AUTOSAR XML (schema 4-3-0)
package /CAN3/ISignalGroup
  11 x i signal group:
    CAN3_SG_BMS1: i-signal=CAN3_HVBattVolt, system-signal-group=CAN3_SG_BMS1
    CAN3_SG_BMS6: i-signal=CAN3_HVBContactorSta, system-signal-group=CAN3_SG_BMS6
    CAN3_SG_FD3_C100_0: i-signal=[CAN3_BatteryMode, CAN3_Rr_Coolantflow, CAN3_Rr_Coolanttemp], system-signal-group=CAN3_SG_FD3_C100_0
    CAN3_SG_FD3_VCU1: i-signal=[CAN3_ActiveDischReq, CAN3_CS_VCU1, CAN3_PwrSta, CAN3_RC_VCU1, CAN3_ShiftGearPosn], system-signal-group=CAN3_SG_FD3_VCU1
    CAN3_SG_FD3_VCU2: i-signal=[CAN3_CS_VCU2_CAN1, CAN3_RC_VCU2_CAN1, CAN3_Rr_ActvDmpDisabReq, CAN3_Rr_IdcMax, CAN3_Rr_IdcMin, CAN3_Rr_MCUEnaReq, CAN3_Rr_TMTqReq, CAN3_Rr_TorqMax, CAN3_Rr_TorqMin, CAN3_Rr_UdcMax, CAN3_Rr_UdcMin], system-signal-group=CAN3_SG_FD3_VCU2
    CAN3_SG_FD3_VCU5: i-signal=[CAN3_FDC_VCU_RrSpdMax_Req, CAN3_FDC_VCU_RrSpdMin_Req, CAN3_FDC_VCU_RrTMCtrlMode_Req, CAN3_FDC_VCU_RrTMSpd_Req, CAN3_FDC_VCU_RrTMTq_Req, CAN3_FDC_VCU_RrTqMax_Req, CAN3_FDC_VCU_RrTqMin_Req], system-signal-group=CAN3_SG_FD3_VCU5
    CAN3_SG_GW3_CE100_0: i-signal=[CAN3_IVI_Time_Day, CAN3_IVI_Time_Hour, CAN3_IVI_Time_Minute, CAN3_IVI_Time_Month, CAN3_IVI_Time_Second, CAN3_VehSpeed], system-signal-group=CAN3_SG_GW3_CE100_0
    CAN3_SG_MCU_B_R1: i-signal=[CAN3_MCUWarn_R, CAN3_MCU_B_R_IGBTDdeTemp_Sta, CAN3_MCU_B_R_RealPwrKw_Sta, CAN3_Rr_ActvDmpDisabSta, CAN3_Rr_EDUDrtSta, CAN3_Rr_EDUOpratingSta, CAN3_Rr_EDURealTMTq, CAN3_Rr_EDURotateDirction, CAN3_Rr_EDUTqReqFbk, CAN3_Rr_MCU1Chksum, CAN3_Rr_MCU1RolCnt, CAN3_Rr_MCUBAT, CAN3_Rr_MCUDCBusCurr, CAN3_Rr_MCUDCBusVolt, CAN3_Rr_MCUDischrgSta, CAN3_Rr_MCUEnaSta, CAN3_Rr_MCUErr, CAN3_Rr_MCUIGN_sta, CAN3_Rr_MCUReady, CAN3_Rr_MCUReady4Pre, CAN3_Rr_MCUSysSta, CAN3_Rr_MCUTemp, CAN3_Rr_MotorAvailTq, CAN3_Rr_RegenAvailTq, CAN3_Rr_Reserved_bits, CAN3_Rr_TMSpd, CAN3_Rr_TMTemp, CAN3_Rr_TMid, CAN3_Rr_TMiq], system-signal-group=CAN3_SG_MCU_B_R1
    CAN3_SG_MCU_B_R2: i-signal=[CAN3_MCU_B_R_FailLv_Sta, CAN3_MCU_B_R_KL302TqCnt_Sta, CAN3_MCU_B_R_LLCTempWarn_Sta, CAN3_Rr_CoolanttempReq, CAN3_Rr_Failcode1, CAN3_Rr_Failcode2, CAN3_Rr_Failcodehistory1, CAN3_Rr_Failcodehistory2, CAN3_Rr_LLCTemp, CAN3_Rr_LLCflowReq, CAN3_Rr_MCU2Chksum, CAN3_Rr_MCU2RolCnt, CAN3_Rr_MCU3_HW_Ver, CAN3_Rr_MCU3_SW_Ver, CAN3_Rr_MCUTempWarn, CAN3_Rr_TMTempWarn], system-signal-group=CAN3_SG_MCU_B_R2
    CAN3_SG_MCU_B_R_Debug1: i-signal=[CAN3_MCU_R_ID_REF, CAN3_MCU_R_IQ_REF, CAN3_MCU_R_Reserve0, CAN3_MCU_R_Reserve1, CAN3_MCU_R_Reserve2, CAN3_R_FD_FACTCODE_N, CAN3_R_FD_FACTCODE_P, CAN3_R_ID_TQ_LIM_N, CAN3_R_ID_TQ_LIM_P, CAN3_R_K_TQ_LIM_N, CAN3_R_K_TQ_LIM_P, CAN3_R_OffsetAngle, CAN3_R_TQ_LIM_N, CAN3_R_TQ_LIM_P], system-signal-group=CAN3_SG_MCU_B_R_Debug1
    CAN3_SG_MCU_FVT_R1: i-signal=[CAN3_MCU_FVT_R_BoostOP_Sta, CAN3_MCU_FVT_R_EDUTqReq_Fbk, CAN3_MCU_FVT_R_Failcode3_Sta, CAN3_MCU_FVT_R_HeatingOP_Sta, CAN3_MCU_FVT_R_MCUBAT_Sta, CAN3_MCU_FVT_R_MCUErr_Sta, CAN3_MCU_FVT_R_MCUSys_Sta, CAN3_MCU_FVT_R_OilTemp_Sta, CAN3_MCU_FVT_R_TMSpd_Sta], system-signal-group=CAN3_SG_MCU_FVT_R1
package /CAN3/Cluster
  can cluster CAN3: baudrate=500, can-fd-baudrate=2000
    can physical channel CAN3: comm-connectors=ConnCAN3
      frame CAN3_BMS1: id 0x171, frame-length=16, can-addressing-mode=STANDARD, can-fd-frame-support=true, can-frame-rx-behavior=CAN-FD, can-frame-tx-behavior=CAN-FD
        pdu CAN3_BMS1: length=16, minimum-delay=0.0, transmission-mode-true-timing=cyclic-timing=time-period=0.01, unused-bit-pattern=0
          mapping CAN3_SG_BMS1: i-signal-group=CAN3_SG_BMS1, start-position=0, transfer-property=PENDING
          signal CAN3_HVBattVolt: start 28, 13 bit, big-endian, i-signal-type=PRIMITIVE, init-value=constant-reference=Init_CAN3_HVBattVolt, base-type=uint16, implementation-data-type=uint16, transfer-property=PENDING
      frame CAN3_BMS6: id 0x17A, frame-length=12, can-addressing-mode=STANDARD, can-fd-frame-support=true, can-frame-rx-behavior=CAN-FD, can-frame-tx-behavior=CAN-FD
        pdu CAN3_BMS6: length=12, minimum-delay=0.0, transmission-mode-true-timing={cyclic-timing=time-period=0.1, event-controlled-timing={number-of-repetitions=0, repetition-period=0}}, unused-bit-pattern=0
          mapping CAN3_SG_BMS6: i-signal-group=CAN3_SG_BMS6, start-position=0, transfer-property=TRIGGERED-ON-CHANGE
          signal CAN3_HVBContactorSta: start 66, 1 bit, big-endian, i-signal-type=PRIMITIVE, init-value=constant-reference=Init_CAN3_HVBContactorSta, base-type=uint8, implementation-data-type=uint8, transfer-property=TRIGGERED-ON-CHANGE
      frame CAN3_DiagFuncReqFT: id 0x7D0, frame-length=8, can-addressing-mode=STANDARD, can-fd-frame-support=true, can-frame-rx-behavior=CAN-FD, can-frame-tx-behavior=CAN-FD
        n pdu CAN3_DiagFuncReqFT: length=8
      frame CAN3_DiagFuncReqOBD: id 0x7DF, frame-length=8, can-addressing-mode=STANDARD, can-fd-frame-support=true, can-frame-rx-behavior=CAN-FD, can-frame-tx-behavior=CAN-FD
        n pdu CAN3_DiagFuncReqOBD: length=8
      frame CAN3_DiagPhysReqToEOP_FVT_R: id 0x6C3, frame-length=8, can-addressing-mode=STANDARD, can-fd-frame-support=true, can-frame-rx-behavior=CAN-FD, can-frame-tx-behavior=CAN-FD
        n pdu CAN3_DiagPhysReqToEOP_FVT_R: length=8
      frame CAN3_DiagPhysReqToMCU_B_R: id 0x689, frame-length=64, can-addressing-mode=STANDARD, can-fd-frame-support=true, can-frame-rx-behavior=CAN-FD, can-frame-tx-behavior=CAN-FD
        n pdu CAN3_DiagPhysReqToMCU_B_R: length=8
      frame CAN3_DiagRespFromEOP_FVT_R: id 0x643, frame-length=8, can-addressing-mode=STANDARD, can-fd-frame-support=true, can-frame-rx-behavior=CAN-FD, can-frame-tx-behavior=CAN-FD
        n pdu CAN3_DiagRespFromEOP_FVT_R: length=8
      frame CAN3_DiagRespFromMCU_B_R: id 0x609, frame-length=64, can-addressing-mode=STANDARD, can-fd-frame-support=true, can-frame-rx-behavior=CAN-FD, can-frame-tx-behavior=CAN-FD
        n pdu CAN3_DiagRespFromMCU_B_R: length=8
      frame CAN3_FD3_C100_0: id 0x182, frame-length=20, can-addressing-mode=STANDARD, can-fd-frame-support=true, can-frame-rx-behavior=CAN-FD, can-frame-tx-behavior=CAN-FD
        pdu CAN3_FD3_C100_0: length=20, minimum-delay=0.0, transmission-mode-true-timing=cyclic-timing=time-period=0.1, unused-bit-pattern=0
          mapping CAN3_SG_FD3_C100_0: i-signal-group=CAN3_SG_FD3_C100_0, start-position=0, transfer-property=PENDING
          signal CAN3_BatteryMode: start 118, 3 bit, big-endian, i-signal-type=PRIMITIVE, init-value=constant-reference=Init_CAN3_BatteryMode, base-type=uint8, implementation-data-type=uint8, transfer-property=PENDING
          signal CAN3_Rr_Coolantflow: start 150, 6 bit, big-endian, i-signal-type=PRIMITIVE, init-value=constant-reference=Init_CAN3_Rr_Coolantflow, base-type=uint8, implementation-data-type=uint8, transfer-property=PENDING
          signal CAN3_Rr_Coolanttemp: start 144, 9 bit, big-endian, i-signal-type=PRIMITIVE, init-value=constant-reference=Init_CAN3_Rr_Coolanttemp, base-type=uint16, implementation-data-type=uint16, transfer-property=PENDING
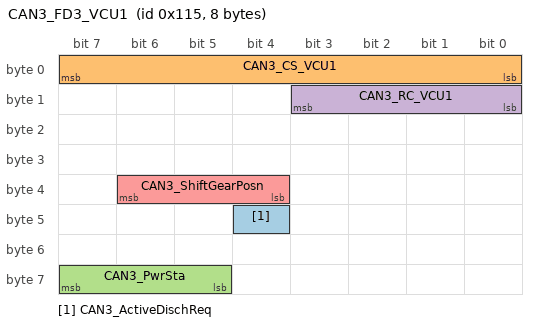
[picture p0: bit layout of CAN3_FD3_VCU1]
      frame CAN3_FD3_VCU1: id 0x115, frame-length=8, can-addressing-mode=STANDARD, can-fd-frame-support=true, can-frame-rx-behavior=CAN-FD, can-frame-tx-behavior=CAN-FD
        pdu CAN3_FD3_VCU1: length=8, minimum-delay=0.0, transmission-mode-true-timing={cyclic-timing=time-period=0.1, event-controlled-timing={number-of-repetitions=0, repetition-period=0}}, unused-bit-pattern=0
          mapping CAN3_SG_FD3_VCU1: i-signal-group=CAN3_SG_FD3_VCU1, start-position=0, transfer-property=TRIGGERED-ON-CHANGE
          signal CAN3_ActiveDischReq: start 44, 1 bit, big-endian, i-signal-type=PRIMITIVE, init-value=constant-reference=Init_CAN3_ActiveDischReq, base-type=uint8, implementation-data-type=uint8, transfer-property=TRIGGERED-ON-CHANGE
          signal CAN3_CS_VCU1: start 7, 8 bit, big-endian, i-signal-type=PRIMITIVE, init-value=constant-reference=Init_CAN3_CS_VCU1, base-type=uint8, implementation-data-type=uint8, transfer-property=PENDING
          signal CAN3_PwrSta: start 63, 3 bit, big-endian, i-signal-type=PRIMITIVE, init-value=constant-reference=Init_CAN3_PwrSta, base-type=uint8, implementation-data-type=uint8, transfer-property=TRIGGERED-ON-CHANGE
          signal CAN3_RC_VCU1: start 11, 4 bit, big-endian, i-signal-type=PRIMITIVE, init-value=constant-reference=Init_CAN3_RC_VCU1, base-type=uint8, implementation-data-type=uint8, transfer-property=PENDING
          signal CAN3_ShiftGearPosn: start 38, 3 bit, big-endian, i-signal-type=PRIMITIVE, init-value=constant-reference=Init_CAN3_ShiftGearPosn, base-type=uint8, implementation-data-type=uint8, transfer-property=TRIGGERED-ON-CHANGE
      frame CAN3_FD3_VCU2: id 0x153, frame-length=32, can-addressing-mode=STANDARD, can-fd-frame-support=true, can-frame-rx-behavior=CAN-FD, can-frame-tx-behavior=CAN-FD
        pdu CAN3_FD3_VCU2: length=32, minimum-delay=0.0, transmission-mode-true-timing=cyclic-timing=time-period=0.01, unused-bit-pattern=0
          mapping CAN3_SG_FD3_VCU2: i-signal-group=CAN3_SG_FD3_VCU2, start-position=0, transfer-property=PENDING
          signal CAN3_CS_VCU2_CAN1: start 7, 8 bit, big-endian, i-signal-type=PRIMITIVE, init-value=constant-reference=Init_CAN3_CS_VCU2_CAN1, base-type=uint8, implementation-data-type=uint8, transfer-property=PENDING
          signal CAN3_RC_VCU2_CAN1: start 11, 4 bit, big-endian, i-signal-type=PRIMITIVE, init-value=constant-reference=Init_CAN3_RC_VCU2_CAN1, base-type=uint8, implementation-data-type=uint8, transfer-property=PENDING
          signal CAN3_Rr_ActvDmpDisabReq: start 196, 1 bit, big-endian, i-signal-type=PRIMITIVE, init-value=constant-reference=Init_CAN3_Rr_ActvDmpDisabReq, base-type=uint8, implementation-data-type=uint8, transfer-property=PENDING
          signal CAN3_Rr_IdcMax: start 23, 12 bit, big-endian, i-signal-type=PRIMITIVE, init-value=constant-reference=Init_CAN3_Rr_IdcMax, base-type=uint16, implementation-data-type=uint16, transfer-property=PENDING
          signal CAN3_Rr_IdcMin: start 27, 12 bit, big-endian, i-signal-type=PRIMITIVE, init-value=constant-reference=Init_CAN3_Rr_IdcMin, base-type=uint16, implementation-data-type=uint16, transfer-property=PENDING
          signal CAN3_Rr_MCUEnaReq: start 197, 1 bit, big-endian, i-signal-type=PRIMITIVE, init-value=constant-reference=Init_CAN3_Rr_MCUEnaReq, base-type=uint8, implementation-data-type=uint8, transfer-property=PENDING
          signal CAN3_Rr_TMTqReq: start 119, 16 bit, big-endian, i-signal-type=PRIMITIVE, init-value=constant-reference=Init_CAN3_Rr_TMTqReq, base-type=uint16, implementation-data-type=uint16, transfer-property=PENDING
          signal CAN3_Rr_TorqMax: start 47, 12 bit, big-endian, i-signal-type=PRIMITIVE, init-value=constant-reference=Init_CAN3_Rr_TorqMax, base-type=uint16, implementation-data-type=uint16, transfer-property=PENDING
          signal CAN3_Rr_TorqMin: start 51, 12 bit, big-endian, i-signal-type=PRIMITIVE, init-value=constant-reference=Init_CAN3_Rr_TorqMin, base-type=uint16, implementation-data-type=uint16, transfer-property=PENDING
          signal CAN3_Rr_UdcMax: start 71, 12 bit, big-endian, i-signal-type=PRIMITIVE, init-value=constant-reference=Init_CAN3_Rr_UdcMax, base-type=uint16, implementation-data-type=uint16, transfer-property=PENDING
          signal CAN3_Rr_UdcMin: start 75, 12 bit, big-endian, i-signal-type=PRIMITIVE, init-value=constant-reference=Init_CAN3_Rr_UdcMin, base-type=uint16, implementation-data-type=uint16, transfer-property=PENDING
      frame CAN3_FD3_VCU5: id 0x155, frame-length=32, can-addressing-mode=STANDARD, can-fd-frame-support=true, can-frame-rx-behavior=CAN-FD, can-frame-tx-behavior=CAN-FD
        pdu CAN3_FD3_VCU5: length=32, minimum-delay=0.0, transmission-mode-true-timing=cyclic-timing=time-period=0.01, unused-bit-pattern=0
          mapping CAN3_SG_FD3_VCU5: i-signal-group=CAN3_SG_FD3_VCU5, start-position=0, transfer-property=PENDING
          signal CAN3_FDC_VCU_RrSpdMax_Req: start 103, 16 bit, big-endian, i-signal-type=PRIMITIVE, init-value=constant-reference=Init_CAN3_FDC_VCU_RrSpdMax_Req, base-type=uint16, implementation-data-type=uint16, transfer-property=PENDING
          signal CAN3_FDC_VCU_RrSpdMin_Req: start 135, 16 bit, big-endian, i-signal-type=PRIMITIVE, init-value=constant-reference=Init_CAN3_FDC_VCU_RrSpdMin_Req, base-type=uint16, implementation-data-type=uint16, transfer-property=PENDING
          signal CAN3_FDC_VCU_RrTMCtrlMode_Req: start 47, 3 bit, big-endian, i-signal-type=PRIMITIVE, init-value=constant-reference=Init_CAN3_FDC_VCU_RrTMCtrlMode_Req, base-type=uint8, implementation-data-type=uint8, transfer-property=PENDING
          signal CAN3_FDC_VCU_RrTMSpd_Req: start 167, 16 bit, big-endian, i-signal-type=PRIMITIVE, init-value=constant-reference=Init_CAN3_FDC_VCU_RrTMSpd_Req, base-type=uint16, implementation-data-type=uint16, transfer-property=PENDING
          signal CAN3_FDC_VCU_RrTMTq_Req: start 199, 16 bit, big-endian, i-signal-type=PRIMITIVE, init-value=constant-reference=Init_CAN3_FDC_VCU_RrTMTq_Req, base-type=uint16, implementation-data-type=uint16, transfer-property=PENDING
          signal CAN3_FDC_VCU_RrTqMax_Req: start 219, 12 bit, big-endian, i-signal-type=PRIMITIVE, init-value=constant-reference=Init_CAN3_FDC_VCU_RrTqMax_Req, base-type=uint16, implementation-data-type=uint16, transfer-property=PENDING
          signal CAN3_FDC_VCU_RrTqMin_Req: start 243, 12 bit, big-endian, i-signal-type=PRIMITIVE, init-value=constant-reference=Init_CAN3_FDC_VCU_RrTqMin_Req, base-type=uint16, implementation-data-type=uint16, transfer-property=PENDING
      frame CAN3_GW3_CE100_0: id 0x1C3, frame-length=32, can-addressing-mode=STANDARD, can-fd-frame-support=true, can-frame-rx-behavior=CAN-FD, can-frame-tx-behavior=CAN-FD
        pdu CAN3_GW3_CE100_0: length=32, minimum-delay=0.0, transmission-mode-true-timing={cyclic-timing=time-period=0.1, event-controlled-timing={number-of-repetitions=0, repetition-period=0}}, unused-bit-pattern=0
          mapping CAN3_SG_GW3_CE100_0: i-signal-group=CAN3_SG_GW3_CE100_0, start-position=0, transfer-property=TRIGGERED-ON-CHANGE
          signal CAN3_IVI_Time_Day: start 228, 5 bit, big-endian, i-signal-type=PRIMITIVE, init-value=constant-reference=Init_CAN3_IVI_Time_Day, base-type=uint8, implementation-data-type=uint8, transfer-property=PENDING
          signal CAN3_IVI_Time_Hour: start 236, 5 bit, big-endian, i-signal-type=PRIMITIVE, init-value=constant-reference=Init_CAN3_IVI_Time_Hour, base-type=uint8, implementation-data-type=uint8, transfer-property=PENDING
          signal CAN3_IVI_Time_Minute: start 245, 6 bit, big-endian, i-signal-type=PRIMITIVE, init-value=constant-reference=Init_CAN3_IVI_Time_Minute, base-type=uint8, implementation-data-type=uint8, transfer-property=PENDING
          signal CAN3_IVI_Time_Month: start 219, 4 bit, big-endian, i-signal-type=PRIMITIVE, init-value=constant-reference=Init_CAN3_IVI_Time_Month, base-type=uint8, implementation-data-type=uint8, transfer-property=PENDING
          signal CAN3_IVI_Time_Second: start 253, 6 bit, big-endian, i-signal-type=PRIMITIVE, init-value=constant-reference=Init_CAN3_IVI_Time_Second, base-type=uint8, implementation-data-type=uint8, transfer-property=PENDING
          signal CAN3_VehSpeed: start 19, 12 bit, big-endian, i-signal-type=PRIMITIVE, init-value=constant-reference=Init_CAN3_VehSpeed, base-type=uint16, implementation-data-type=uint16, transfer-property=PENDING
      frame CAN3_MCU_B_R1: id 0x190, frame-length=32, can-addressing-mode=STANDARD, can-fd-frame-support=true, can-frame-rx-behavior=CAN-FD, can-frame-tx-behavior=CAN-FD
        pdu CAN3_MCU_B_R1: length=32, minimum-delay=0.0, transmission-mode-true-timing=cyclic-timing=time-period=0.01, unused-bit-pattern=0
          mapping CAN3_SG_MCU_B_R1: i-signal-group=CAN3_SG_MCU_B_R1, start-position=0, transfer-property=PENDING
          signal CAN3_MCUWarn_R: start 62, 3 bit, big-endian, i-signal-type=PRIMITIVE, init-value=constant-reference=Init_CAN3_MCUWarn_R, base-type=uint8, implementation-data-type=uint8, transfer-property=PENDING
          signal CAN3_MCU_B_R_IGBTDdeTemp_Sta: start 24, 9 bit, big-endian, i-signal-type=PRIMITIVE, init-value=constant-reference=Init_CAN3_MCU_B_R_IGBTDdeTemp_Sta, base-type=uint16, implementation-data-type=uint16, transfer-property=PENDING
          signal CAN3_MCU_B_R_RealPwrKw_Sta: start 47, 16 bit, big-endian, i-signal-type=PRIMITIVE, init-value=constant-reference=Init_CAN3_MCU_B_R_RealPwrKw_Sta, base-type=uint16, implementation-data-type=uint16, transfer-property=PENDING
          signal CAN3_Rr_ActvDmpDisabSta: start 201, 1 bit, big-endian, i-signal-type=PRIMITIVE, init-value=constant-reference=Init_CAN3_Rr_ActvDmpDisabSta, base-type=uint8, implementation-data-type=uint8, transfer-property=PENDING
          signal CAN3_Rr_EDUDrtSta: start 202, 1 bit, big-endian, i-signal-type=PRIMITIVE, init-value=constant-reference=Init_CAN3_Rr_EDUDrtSta, base-type=uint8, implementation-data-type=uint8, transfer-property=PENDING
          signal CAN3_Rr_EDUOpratingSta: start 245, 1 bit, big-endian, i-signal-type=PRIMITIVE, init-value=constant-reference=Init_CAN3_Rr_EDUOpratingSta, base-type=uint8, implementation-data-type=uint8, transfer-property=PENDING
          signal CAN3_Rr_EDURealTMTq: start 231, 16 bit, big-endian, i-signal-type=PRIMITIVE, init-value=constant-reference=Init_CAN3_Rr_EDURealTMTq, base-type=uint16, implementation-data-type=uint16, transfer-property=PENDING
          signal CAN3_Rr_EDURotateDirction: start 247, 2 bit, big-endian, i-signal-type=PRIMITIVE, init-value=constant-reference=Init_CAN3_Rr_EDURotateDirction, base-type=uint8, implementation-data-type=uint8, transfer-property=PENDING
          signal CAN3_Rr_EDUTqReqFbk: start 243, 12 bit, big-endian, i-signal-type=PRIMITIVE, init-value=constant-reference=Init_CAN3_Rr_EDUTqReqFbk, base-type=uint16, implementation-data-type=uint16, transfer-property=PENDING
          signal CAN3_Rr_MCU1Chksum: start 7, 8 bit, big-endian, i-signal-type=PRIMITIVE, init-value=constant-reference=Init_CAN3_Rr_MCU1Chksum, base-type=uint8, implementation-data-type=uint8, transfer-property=PENDING
          signal CAN3_Rr_MCU1RolCnt: start 11, 4 bit, big-endian, i-signal-type=PRIMITIVE, init-value=constant-reference=Init_CAN3_Rr_MCU1RolCnt, base-type=uint8, implementation-data-type=uint8, transfer-property=PENDING
          signal CAN3_Rr_MCUBAT: start 71, 8 bit, big-endian, i-signal-type=PRIMITIVE, init-value=constant-reference=Init_CAN3_Rr_MCUBAT, base-type=uint8, implementation-data-type=uint8, transfer-property=PENDING
          signal CAN3_Rr_MCUDCBusCurr: start 174, 15 bit, big-endian, i-signal-type=PRIMITIVE, init-value=constant-reference=Init_CAN3_Rr_MCUDCBusCurr, base-type=uint16, implementation-data-type=uint16, transfer-property=PENDING
          signal CAN3_Rr_MCUDCBusVolt: start 191, 16 bit, big-endian, i-signal-type=PRIMITIVE, init-value=constant-reference=Init_CAN3_Rr_MCUDCBusVolt, base-type=uint16, implementation-data-type=uint16, transfer-property=PENDING
          signal CAN3_Rr_MCUDischrgSta: start 203, 1 bit, big-endian, i-signal-type=PRIMITIVE, init-value=constant-reference=Init_CAN3_Rr_MCUDischrgSta, base-type=uint8, implementation-data-type=uint8, transfer-property=PENDING
          signal CAN3_Rr_MCUEnaSta: start 244, 1 bit, big-endian, i-signal-type=PRIMITIVE, init-value=constant-reference=Init_CAN3_Rr_MCUEnaSta, base-type=uint8, implementation-data-type=uint8, transfer-property=PENDING
          signal CAN3_Rr_MCUErr: start 143, 8 bit, big-endian, i-signal-type=PRIMITIVE, init-value=constant-reference=Init_CAN3_Rr_MCUErr, base-type=uint8, implementation-data-type=uint8, transfer-property=PENDING
          signal CAN3_Rr_MCUIGN_sta: start 72, 1 bit, big-endian, i-signal-type=PRIMITIVE, init-value=constant-reference=Init_CAN3_Rr_MCUIGN_sta, base-type=uint8, implementation-data-type=uint8, transfer-property=PENDING
          signal CAN3_Rr_MCUReady: start 63, 1 bit, big-endian, i-signal-type=PRIMITIVE, init-value=constant-reference=Init_CAN3_Rr_MCUReady, base-type=uint8, implementation-data-type=uint8, transfer-property=PENDING
          signal CAN3_Rr_MCUReady4Pre: start 200, 1 bit, big-endian, i-signal-type=PRIMITIVE, init-value=constant-reference=Init_CAN3_Rr_MCUReady4Pre, base-type=uint8, implementation-data-type=uint8, transfer-property=PENDING
          signal CAN3_Rr_MCUSysSta: start 59, 4 bit, big-endian, i-signal-type=PRIMITIVE, init-value=constant-reference=Init_CAN3_Rr_MCUSysSta, base-type=uint8, implementation-data-type=uint8, transfer-property=PENDING
          signal CAN3_Rr_MCUTemp: start 167, 9 bit, big-endian, i-signal-type=PRIMITIVE, init-value=constant-reference=Init_CAN3_Rr_MCUTemp, base-type=uint16, implementation-data-type=uint16, transfer-property=PENDING
          signal CAN3_Rr_MotorAvailTq: start 91, 12 bit, big-endian, i-signal-type=PRIMITIVE, init-value=constant-reference=Init_CAN3_Rr_MotorAvailTq, base-type=uint16, implementation-data-type=uint16, transfer-property=PENDING
          signal CAN3_Rr_RegenAvailTq: start 87, 12 bit, big-endian, i-signal-type=PRIMITIVE, init-value=constant-reference=Init_CAN3_Rr_RegenAvailTq, base-type=uint16, implementation-data-type=uint16, transfer-property=PENDING
          signal CAN3_Rr_Reserved_bits: start 79, 7 bit, big-endian, i-signal-type=PRIMITIVE, init-value=constant-reference=Init_CAN3_Rr_Reserved_bits, base-type=uint8, implementation-data-type=uint8, transfer-property=PENDING
          signal CAN3_Rr_TMSpd: start 215, 16 bit, big-endian, i-signal-type=PRIMITIVE, init-value=constant-reference=Init_CAN3_Rr_TMSpd, base-type=uint16, implementation-data-type=uint16, transfer-property=PENDING
          signal CAN3_Rr_TMTemp: start 144, 9 bit, big-endian, i-signal-type=PRIMITIVE, init-value=constant-reference=Init_CAN3_Rr_TMTemp, base-type=uint16, implementation-data-type=uint16, transfer-property=PENDING
          signal CAN3_Rr_TMid: start 126, 15 bit, big-endian, i-signal-type=PRIMITIVE, init-value=constant-reference=Init_CAN3_Rr_TMid, base-type=uint16, implementation-data-type=uint16, transfer-property=PENDING
          signal CAN3_Rr_TMiq: start 110, 15 bit, big-endian, i-signal-type=PRIMITIVE, init-value=constant-reference=Init_CAN3_Rr_TMiq, base-type=uint16, implementation-data-type=uint16, transfer-property=PENDING
      frame CAN3_MCU_B_R2: id 0x193, frame-length=16, can-addressing-mode=STANDARD, can-fd-frame-support=true, can-frame-rx-behavior=CAN-FD, can-frame-tx-behavior=CAN-FD
        pdu CAN3_MCU_B_R2: length=16, minimum-delay=0.0, transmission-mode-true-timing=cyclic-timing=time-period=0.01, unused-bit-pattern=0
          mapping CAN3_SG_MCU_B_R2: i-signal-group=CAN3_SG_MCU_B_R2, start-position=0, transfer-property=PENDING
          signal CAN3_MCU_B_R_FailLv_Sta: start 27, 3 bit, big-endian, i-signal-type=PRIMITIVE, init-value=constant-reference=Init_CAN3_MCU_B_R_FailLv_Sta, base-type=uint8, implementation-data-type=uint8, transfer-property=PENDING
          signal CAN3_MCU_B_R_KL302TqCnt_Sta: start 71, 8 bit, big-endian, i-signal-type=PRIMITIVE, init-value=constant-reference=Init_CAN3_MCU_B_R_KL302TqCnt_Sta, base-type=uint8, implementation-data-type=uint8, transfer-property=PENDING
          signal CAN3_MCU_B_R_LLCTempWarn_Sta: start 23, 2 bit, big-endian, i-signal-type=PRIMITIVE, init-value=constant-reference=Init_CAN3_MCU_B_R_LLCTempWarn_Sta, base-type=uint8, implementation-data-type=uint8, transfer-property=PENDING
          signal CAN3_Rr_CoolanttempReq: start 24, 9 bit, big-endian, i-signal-type=PRIMITIVE, init-value=constant-reference=Init_CAN3_Rr_CoolanttempReq, base-type=uint16, implementation-data-type=uint16, transfer-property=PENDING
          signal CAN3_Rr_Failcode1: start 63, 8 bit, big-endian, i-signal-type=PRIMITIVE, init-value=constant-reference=Init_CAN3_Rr_Failcode1, base-type=uint8, implementation-data-type=uint8, transfer-property=PENDING
          signal CAN3_Rr_Failcode2: start 55, 8 bit, big-endian, i-signal-type=PRIMITIVE, init-value=constant-reference=Init_CAN3_Rr_Failcode2, base-type=uint8, implementation-data-type=uint8, transfer-property=PENDING
          signal CAN3_Rr_Failcodehistory1: start 41, 2 bit, big-endian, i-signal-type=PRIMITIVE, init-value=constant-reference=Init_CAN3_Rr_Failcodehistory1, base-type=uint8, implementation-data-type=uint8, transfer-property=PENDING
          signal CAN3_Rr_Failcodehistory2: start 43, 2 bit, big-endian, i-signal-type=PRIMITIVE, init-value=constant-reference=Init_CAN3_Rr_Failcodehistory2, base-type=uint8, implementation-data-type=uint8, transfer-property=PENDING
          signal CAN3_Rr_LLCTemp: start 80, 9 bit, big-endian, i-signal-type=PRIMITIVE, init-value=constant-reference=Init_CAN3_Rr_LLCTemp, base-type=uint16, implementation-data-type=uint16, transfer-property=PENDING
          signal CAN3_Rr_LLCflowReq: start 21, 6 bit, big-endian, i-signal-type=PRIMITIVE, init-value=constant-reference=Init_CAN3_Rr_LLCflowReq, base-type=uint8, implementation-data-type=uint8, transfer-property=PENDING
          signal CAN3_Rr_MCU2Chksum: start 7, 8 bit, big-endian, i-signal-type=PRIMITIVE, init-value=constant-reference=Init_CAN3_Rr_MCU2Chksum, base-type=uint8, implementation-data-type=uint8, transfer-property=PENDING
          signal CAN3_Rr_MCU2RolCnt: start 11, 4 bit, big-endian, i-signal-type=PRIMITIVE, init-value=constant-reference=Init_CAN3_Rr_MCU2RolCnt, base-type=uint8, implementation-data-type=uint8, transfer-property=PENDING
          signal CAN3_Rr_MCU3_HW_Ver: start 103, 16 bit, big-endian, i-signal-type=PRIMITIVE, init-value=constant-reference=Init_CAN3_Rr_MCU3_HW_Ver, base-type=uint16, implementation-data-type=uint16, transfer-property=PENDING
          signal CAN3_Rr_MCU3_SW_Ver: start 119, 16 bit, big-endian, i-signal-type=PRIMITIVE, init-value=constant-reference=Init_CAN3_Rr_MCU3_SW_Ver, base-type=uint16, implementation-data-type=uint16, transfer-property=PENDING
          signal CAN3_Rr_MCUTempWarn: start 47, 2 bit, big-endian, i-signal-type=PRIMITIVE, init-value=constant-reference=Init_CAN3_Rr_MCUTempWarn, base-type=uint8, implementation-data-type=uint8, transfer-property=PENDING
          signal CAN3_Rr_TMTempWarn: start 45, 2 bit, big-endian, i-signal-type=PRIMITIVE, init-value=constant-reference=Init_CAN3_Rr_TMTempWarn, base-type=uint8, implementation-data-type=uint8, transfer-property=PENDING
      frame CAN3_MCU_B_R_Debug1: id 0x4F5, frame-length=32, can-addressing-mode=STANDARD, can-fd-frame-support=true, can-frame-rx-behavior=CAN-FD, can-frame-tx-behavior=CAN-FD
        pdu CAN3_MCU_B_R_Debug1: length=32, minimum-delay=0.0, transmission-mode-true-timing=cyclic-timing=time-period=0.01, unused-bit-pattern=0
          mapping CAN3_SG_MCU_B_R_Debug1: i-signal-group=CAN3_SG_MCU_B_R_Debug1, start-position=0, transfer-property=PENDING
          signal CAN3_MCU_R_ID_REF: start 39, 32 bit, big-endian, i-signal-type=PRIMITIVE, init-value=constant-reference=Init_CAN3_MCU_R_ID_REF, base-type=uint32, implementation-data-type=uint32, transfer-property=PENDING
          signal CAN3_MCU_R_IQ_REF: start 7, 32 bit, big-endian, i-signal-type=PRIMITIVE, init-value=constant-reference=Init_CAN3_MCU_R_IQ_REF, base-type=uint32, implementation-data-type=uint32, transfer-property=PENDING
          signal CAN3_MCU_R_Reserve0: start 119, 16 bit, big-endian, i-signal-type=PRIMITIVE, init-value=constant-reference=Init_CAN3_MCU_R_Reserve0, base-type=uint16, implementation-data-type=uint16, transfer-property=PENDING
          signal CAN3_MCU_R_Reserve1: start 103, 16 bit, big-endian, i-signal-type=PRIMITIVE, init-value=constant-reference=Init_CAN3_MCU_R_Reserve1, base-type=uint16, implementation-data-type=uint16, transfer-property=PENDING
          signal CAN3_MCU_R_Reserve2: start 87, 16 bit, big-endian, i-signal-type=PRIMITIVE, init-value=constant-reference=Init_CAN3_MCU_R_Reserve2, base-type=uint16, implementation-data-type=uint16, transfer-property=PENDING
          signal CAN3_R_FD_FACTCODE_N: start 191, 8 bit, big-endian, i-signal-type=PRIMITIVE, init-value=constant-reference=Init_CAN3_R_FD_FACTCODE_N, base-type=uint8, implementation-data-type=uint8, transfer-property=PENDING
          signal CAN3_R_FD_FACTCODE_P: start 183, 8 bit, big-endian, i-signal-type=PRIMITIVE, init-value=constant-reference=Init_CAN3_R_FD_FACTCODE_P, base-type=uint8, implementation-data-type=uint8, transfer-property=PENDING
          signal CAN3_R_ID_TQ_LIM_N: start 175, 8 bit, big-endian, i-signal-type=PRIMITIVE, init-value=constant-reference=Init_CAN3_R_ID_TQ_LIM_N, base-type=uint8, implementation-data-type=uint8, transfer-property=PENDING
          signal CAN3_R_ID_TQ_LIM_P: start 167, 8 bit, big-endian, i-signal-type=PRIMITIVE, init-value=constant-reference=Init_CAN3_R_ID_TQ_LIM_P, base-type=uint8, implementation-data-type=uint8, transfer-property=PENDING
          signal CAN3_R_K_TQ_LIM_N: start 159, 8 bit, big-endian, i-signal-type=PRIMITIVE, init-value=constant-reference=Init_CAN3_R_K_TQ_LIM_N, base-type=uint8, implementation-data-type=uint8, transfer-property=PENDING
          signal CAN3_R_K_TQ_LIM_P: start 151, 8 bit, big-endian, i-signal-type=PRIMITIVE, init-value=constant-reference=Init_CAN3_R_K_TQ_LIM_P, base-type=uint8, implementation-data-type=uint8, transfer-property=PENDING
          signal CAN3_R_OffsetAngle: start 71, 16 bit, big-endian, i-signal-type=PRIMITIVE, init-value=constant-reference=Init_CAN3_R_OffsetAngle, base-type=uint16, implementation-data-type=uint16, transfer-property=PENDING
          signal CAN3_R_TQ_LIM_N: start 143, 8 bit, big-endian, i-signal-type=PRIMITIVE, init-value=constant-reference=Init_CAN3_R_TQ_LIM_N, base-type=uint8, implementation-data-type=uint8, transfer-property=PENDING
          signal CAN3_R_TQ_LIM_P: start 135, 8 bit, big-endian, i-signal-type=PRIMITIVE, init-value=constant-reference=Init_CAN3_R_TQ_LIM_P, base-type=uint8, implementation-data-type=uint8, transfer-property=PENDING
      frame CAN3_MCU_FVT_R1: id 0x199, frame-length=20, can-addressing-mode=STANDARD, can-fd-frame-support=true, can-frame-rx-behavior=CAN-FD, can-frame-tx-behavior=CAN-FD
        pdu CAN3_MCU_FVT_R1: length=20, minimum-delay=0.0, transmission-mode-true-timing=cyclic-timing=time-period=0.01, unused-bit-pattern=0
          mapping CAN3_SG_MCU_FVT_R1: i-signal-group=CAN3_SG_MCU_FVT_R1, start-position=0, transfer-property=PENDING
          signal CAN3_MCU_FVT_R_BoostOP_Sta: start 17, 1 bit, big-endian, i-signal-type=PRIMITIVE, init-value=constant-reference=Init_CAN3_MCU_FVT_R_BoostOP_Sta, base-type=uint8, implementation-data-type=uint8, transfer-property=PENDING
          signal CAN3_MCU_FVT_R_EDUTqReq_Fbk: start 71, 16 bit, big-endian, i-signal-type=PRIMITIVE, init-value=constant-reference=Init_CAN3_MCU_FVT_R_EDUTqReq_Fbk, base-type=uint16, implementation-data-type=uint16, transfer-property=PENDING
          signal CAN3_MCU_FVT_R_Failcode3_Sta: start 95, 8 bit, big-endian, i-signal-type=PRIMITIVE, init-value=constant-reference=Init_CAN3_MCU_FVT_R_Failcode3_Sta, base-type=uint8, implementation-data-type=uint8, transfer-property=PENDING
          signal CAN3_MCU_FVT_R_HeatingOP_Sta: start 33, 1 bit, big-endian, i-signal-type=PRIMITIVE, init-value=constant-reference=Init_CAN3_MCU_FVT_R_HeatingOP_Sta, base-type=uint8, implementation-data-type=uint8, transfer-property=PENDING
          signal CAN3_MCU_FVT_R_MCUBAT_Sta: start 16, 9 bit, big-endian, i-signal-type=PRIMITIVE, init-value=constant-reference=Init_CAN3_MCU_FVT_R_MCUBAT_Sta, base-type=uint16, implementation-data-type=uint16, transfer-property=PENDING
          signal CAN3_MCU_FVT_R_MCUErr_Sta: start 87, 8 bit, big-endian, i-signal-type=PRIMITIVE, init-value=constant-reference=Init_CAN3_MCU_FVT_R_MCUErr_Sta, base-type=uint8, implementation-data-type=uint8, transfer-property=PENDING
          signal CAN3_MCU_FVT_R_MCUSys_Sta: start 23, 4 bit, big-endian, i-signal-type=PRIMITIVE, init-value=constant-reference=Init_CAN3_MCU_FVT_R_MCUSys_Sta, base-type=uint8, implementation-data-type=uint8, transfer-property=PENDING
          signal CAN3_MCU_FVT_R_OilTemp_Sta: start 32, 9 bit, big-endian, i-signal-type=PRIMITIVE, init-value=constant-reference=Init_CAN3_MCU_FVT_R_OilTemp_Sta, base-type=uint16, implementation-data-type=uint16, transfer-property=PENDING
          signal CAN3_MCU_FVT_R_TMSpd_Sta: start 55, 16 bit, big-endian, i-signal-type=PRIMITIVE, init-value=constant-reference=Init_CAN3_MCU_FVT_R_TMSpd_Sta, base-type=uint16, implementation-data-type=uint16, transfer-property=PENDING
      frame CAN3_NMm_MCU_TX: id 0x500, frame-length=8, can-addressing-mode=STANDARD, can-fd-frame-support=false, can-frame-rx-behavior=CAN-20, can-frame-tx-behavior=CAN-20
        nm pdu CAN3_NMm_MCU_TX: length=8, unused-bit-pattern=0
      frame CAN3_NMm_MCU_RX: id 0x500, frame-length=8, can-addressing-mode=STANDARD, can-fd-frame-support=false, can-frame-rx-behavior=CAN-20, can-frame-tx-behavior=CAN-20
        nm pdu CAN3_NMm_MCU_RX: length=8, unused-bit-pattern=0
package /CAN3/ConstantSpecification
  113 x constant specification:
    Init_CAN3_HVBattVolt: value-spec=0
    Init_CAN3_HVBContactorSta: value-spec=0
    Init_CAN3_BatteryMode: value-spec=0
    Init_CAN3_Rr_Coolantflow: value-spec=0
    Init_CAN3_Rr_Coolanttemp: value-spec=40
    Init_CAN3_ActiveDischReq: value-spec=0
    Init_CAN3_CS_VCU1: value-spec=0
    Init_CAN3_PwrSta: value-spec=7
    Init_CAN3_RC_VCU1: value-spec=0
    Init_CAN3_ShiftGearPosn: value-spec=1
    Init_CAN3_CS_VCU2_CAN1: value-spec=0
    Init_CAN3_RC_VCU2_CAN1: value-spec=0
    Init_CAN3_Rr_ActvDmpDisabReq: value-spec=0
    Init_CAN3_Rr_IdcMax: value-spec=0
    Init_CAN3_Rr_IdcMin: value-spec=0
    Init_CAN3_Rr_MCUEnaReq: value-spec=0
    Init_CAN3_Rr_TMTqReq: value-spec=5300
    Init_CAN3_Rr_TorqMax: value-spec=0
    Init_CAN3_Rr_TorqMin: value-spec=0
    Init_CAN3_Rr_UdcMax: value-spec=0
    Init_CAN3_Rr_UdcMin: value-spec=0
    Init_CAN3_FDC_VCU_RrSpdMax_Req: value-spec=0
    Init_CAN3_FDC_VCU_RrSpdMin_Req: value-spec=22000
    Init_CAN3_FDC_VCU_RrTMCtrlMode_Req: value-spec=0
    Init_CAN3_FDC_VCU_RrTMSpd_Req: value-spec=22000
    Init_CAN3_FDC_VCU_RrTMTq_Req: value-spec=10000
    Init_CAN3_FDC_VCU_RrTqMax_Req: value-spec=0
    Init_CAN3_FDC_VCU_RrTqMin_Req: value-spec=1022
    Init_CAN3_IVI_Time_Day: value-spec=0
    Init_CAN3_IVI_Time_Hour: value-spec=0
    Init_CAN3_IVI_Time_Minute: value-spec=0
    Init_CAN3_IVI_Time_Month: value-spec=0
    Init_CAN3_IVI_Time_Second: value-spec=0
    Init_CAN3_VehSpeed: value-spec=0
    Init_CAN3_MCUWarn_R: value-spec=7
    Init_CAN3_MCU_B_R_IGBTDdeTemp_Sta: value-spec=40
    Init_CAN3_MCU_B_R_RealPwrKw_Sta: value-spec=5300
    Init_CAN3_Rr_ActvDmpDisabSta: value-spec=0
    Init_CAN3_Rr_EDUDrtSta: value-spec=0
    Init_CAN3_Rr_EDUOpratingSta: value-spec=0
    Init_CAN3_Rr_EDURealTMTq: value-spec=10220
    Init_CAN3_Rr_EDURotateDirction: value-spec=0
    Init_CAN3_Rr_EDUTqReqFbk: value-spec=1022
    Init_CAN3_Rr_MCU1Chksum: value-spec=0
    Init_CAN3_Rr_MCU1RolCnt: value-spec=0
    Init_CAN3_Rr_MCUBAT: value-spec=0
    Init_CAN3_Rr_MCUDCBusCurr: value-spec=15000
    Init_CAN3_Rr_MCUDCBusVolt: value-spec=0
    Init_CAN3_Rr_MCUDischrgSta: value-spec=0
    Init_CAN3_Rr_MCUEnaSta: value-spec=0
    Init_CAN3_Rr_MCUErr: value-spec=0
    Init_CAN3_Rr_MCUIGN_sta: value-spec=0
    Init_CAN3_Rr_MCUReady: value-spec=0
    Init_CAN3_Rr_MCUReady4Pre: value-spec=0
    Init_CAN3_Rr_MCUSysSta: value-spec=0
    Init_CAN3_Rr_MCUTemp: value-spec=0
    Init_CAN3_Rr_MotorAvailTq: value-spec=0
    Init_CAN3_Rr_RegenAvailTq: value-spec=0
    Init_CAN3_Rr_Reserved_bits: value-spec=0
    Init_CAN3_Rr_TMSpd: value-spec=18000
    Init_CAN3_Rr_TMTemp: value-spec=0
    Init_CAN3_Rr_TMid: value-spec=15000
    Init_CAN3_Rr_TMiq: value-spec=15000
    Init_CAN3_MCU_B_R_FailLv_Sta: value-spec=0
    Init_CAN3_MCU_B_R_KL302TqCnt_Sta: value-spec=0
    Init_CAN3_MCU_B_R_LLCTempWarn_Sta: value-spec=0
    Init_CAN3_Rr_CoolanttempReq: value-spec=40
    Init_CAN3_Rr_Failcode1: value-spec=0
    Init_CAN3_Rr_Failcode2: value-spec=0
    Init_CAN3_Rr_Failcodehistory1: value-spec=0
    Init_CAN3_Rr_Failcodehistory2: value-spec=0
    Init_CAN3_Rr_LLCTemp: value-spec=40
    Init_CAN3_Rr_LLCflowReq: value-spec=0
    Init_CAN3_Rr_MCU2Chksum: value-spec=0
    Init_CAN3_Rr_MCU2RolCnt: value-spec=0
    Init_CAN3_Rr_MCU3_HW_Ver: value-spec=0
    Init_CAN3_Rr_MCU3_SW_Ver: value-spec=0
    Init_CAN3_Rr_MCUTempWarn: value-spec=3
    Init_CAN3_Rr_TMTempWarn: value-spec=3
    Init_CAN3_MCU_R_ID_REF: value-spec=0
    Init_CAN3_MCU_R_IQ_REF: value-spec=0
    Init_CAN3_MCU_R_Reserve{0..2}: value-spec=0
    Init_CAN3_R_FD_FACTCODE_N: value-spec=0
    Init_CAN3_R_FD_FACTCODE_P: value-spec=0
    Init_CAN3_R_ID_TQ_LIM_N: value-spec=0
    Init_CAN3_R_ID_TQ_LIM_P: value-spec=0
    Init_CAN3_R_K_TQ_LIM_N: value-spec=0
    Init_CAN3_R_K_TQ_LIM_P: value-spec=0
    Init_CAN3_R_OffsetAngle: value-spec=0
    Init_CAN3_R_TQ_LIM_N: value-spec=0
    Init_CAN3_R_TQ_LIM_P: value-spec=0
    Init_CAN3_MCU_FVT_R_BoostOP_Sta: value-spec=0
    Init_CAN3_MCU_FVT_R_EDUTqReq_Fbk: value-spec=10220
    Init_CAN3_MCU_FVT_R_Failcode3_Sta: value-spec=0
    Init_CAN3_MCU_FVT_R_HeatingOP_Sta: value-spec=0
    Init_CAN3_MCU_FVT_R_MCUBAT_Sta: value-spec=0
    Init_CAN3_MCU_FVT_R_MCUErr_Sta: value-spec=0
    Init_CAN3_MCU_FVT_R_MCUSys_Sta: value-spec=6
    Init_CAN3_MCU_FVT_R_OilTemp_Sta: value-spec=40
    Init_CAN3_MCU_FVT_R_TMSpd_Sta: value-spec=22000
    Init_CAN3_SG_BMS1: value-spec=fields=constant-reference=Init_CAN3_HVBattVolt
    Init_CAN3_SG_BMS6: value-spec=fields=constant-reference=Init_CAN3_HVBContactorSta
    Init_CAN3_SG_FD3_C100_0: value-spec=fields=[Init_CAN3_BatteryMode, Init_CAN3_Rr_Coolantflow, Init_CAN3_Rr_Coolanttemp]
    Init_CAN3_SG_FD3_VCU1: value-spec=fields=[Init_CAN3_ActiveDischReq, Init_CAN3_CS_VCU1, Init_CAN3_PwrSta, Init_CAN3_RC_VCU1, Init_CAN3_ShiftGearPosn]
    Init_CAN3_SG_FD3_VCU2: value-spec=fields=[Init_CAN3_CS_VCU2_CAN1, Init_CAN3_RC_VCU2_CAN1, Init_CAN3_Rr_ActvDmpDisabReq, Init_CAN3_Rr_IdcMax, Init_CAN3_Rr_IdcMin, Init_CAN3_Rr_MCUEnaReq, Init_CAN3_Rr_TMTqReq, Init_CAN3_Rr_TorqMax, Init_CAN3_Rr_TorqMin, Init_CAN3_Rr_UdcMax, Init_CAN3_Rr_UdcMin]
    Init_CAN3_SG_FD3_VCU5: value-spec=fields=[Init_CAN3_FDC_VCU_RrSpdMax_Req, Init_CAN3_FDC_VCU_RrSpdMin_Req, Init_CAN3_FDC_VCU_RrTMCtrlMode_Req, Init_CAN3_FDC_VCU_RrTMSpd_Req, Init_CAN3_FDC_VCU_RrTMTq_Req, Init_CAN3_FDC_VCU_RrTqMax_Req, Init_CAN3_FDC_VCU_RrTqMin_Req]
    Init_CAN3_SG_GW3_CE100_0: value-spec=fields=[Init_CAN3_IVI_Time_Day, Init_CAN3_IVI_Time_Hour, Init_CAN3_IVI_Time_Minute, Init_CAN3_IVI_Time_Month, Init_CAN3_IVI_Time_Second, Init_CAN3_VehSpeed]
    Init_CAN3_SG_MCU_B_R1: value-spec=fields=[Init_CAN3_MCUWarn_R, Init_CAN3_MCU_B_R_IGBTDdeTemp_Sta, Init_CAN3_MCU_B_R_RealPwrKw_Sta, Init_CAN3_Rr_ActvDmpDisabSta, Init_CAN3_Rr_EDUDrtSta, Init_CAN3_Rr_EDUOpratingSta, Init_CAN3_Rr_EDURealTMTq, Init_CAN3_Rr_EDURotateDirction, Init_CAN3_Rr_EDUTqReqFbk, Init_CAN3_Rr_MCU1Chksum, Init_CAN3_Rr_MCU1RolCnt, Init_CAN3_Rr_MCUBAT, Init_CAN3_Rr_MCUDCBusCurr, Init_CAN3_Rr_MCUDCBusVolt, Init_CAN3_Rr_MCUDischrgSta, Init_CAN3_Rr_MCUEnaSta, Init_CAN3_Rr_MCUErr, Init_CAN3_Rr_MCUIGN_sta, Init_CAN3_Rr_MCUReady, Init_CAN3_Rr_MCUReady4Pre, Init_CAN3_Rr_MCUSysSta, Init_CAN3_Rr_MCUTemp, Init_CAN3_Rr_MotorAvailTq, Init_CAN3_Rr_RegenAvailTq, Init_CAN3_Rr_Reserved_bits, Init_CAN3_Rr_TMSpd, Init_CAN3_Rr_TMTemp, Init_CAN3_Rr_TMid, Init_CAN3_Rr_TMiq]
    Init_CAN3_SG_MCU_B_R2: value-spec=fields=[Init_CAN3_MCU_B_R_FailLv_Sta, Init_CAN3_MCU_B_R_KL302TqCnt_Sta, Init_CAN3_MCU_B_R_LLCTempWarn_Sta, Init_CAN3_Rr_CoolanttempReq, Init_CAN3_Rr_Failcode1, Init_CAN3_Rr_Failcode2, Init_CAN3_Rr_Failcodehistory1, Init_CAN3_Rr_Failcodehistory2, Init_CAN3_Rr_LLCTemp, Init_CAN3_Rr_LLCflowReq, Init_CAN3_Rr_MCU2Chksum, Init_CAN3_Rr_MCU2RolCnt, Init_CAN3_Rr_MCU3_HW_Ver, Init_CAN3_Rr_MCU3_SW_Ver, Init_CAN3_Rr_MCUTempWarn, Init_CAN3_Rr_TMTempWarn]
    Init_CAN3_SG_MCU_B_R_Debug1: value-spec=fields=[Init_CAN3_MCU_R_ID_REF, Init_CAN3_MCU_R_IQ_REF, Init_CAN3_MCU_R_Reserve0, Init_CAN3_MCU_R_Reserve1, Init_CAN3_MCU_R_Reserve2, Init_CAN3_R_FD_FACTCODE_N, Init_CAN3_R_FD_FACTCODE_P, Init_CAN3_R_ID_TQ_LIM_N, Init_CAN3_R_ID_TQ_LIM_P, Init_CAN3_R_K_TQ_LIM_N, Init_CAN3_R_K_TQ_LIM_P, Init_CAN3_R_OffsetAngle, Init_CAN3_R_TQ_LIM_N, Init_CAN3_R_TQ_LIM_P]
    Init_CAN3_SG_MCU_FVT_R1: value-spec=fields=[Init_CAN3_MCU_FVT_R_BoostOP_Sta, Init_CAN3_MCU_FVT_R_EDUTqReq_Fbk, Init_CAN3_MCU_FVT_R_Failcode3_Sta, Init_CAN3_MCU_FVT_R_HeatingOP_Sta, Init_CAN3_MCU_FVT_R_MCUBAT_Sta, Init_CAN3_MCU_FVT_R_MCUErr_Sta, Init_CAN3_MCU_FVT_R_MCUSys_Sta, Init_CAN3_MCU_FVT_R_OilTemp_Sta, Init_CAN3_MCU_FVT_R_TMSpd_Sta]
package /CAN3/ImplementationDataTypes
  11 x impl type, all with category=STRUCTURE:
    DT_CAN3_SG_BMS1
      element CAN3_HVBattVolt: implementation-data-type=uint16
    DT_CAN3_SG_BMS6
      element CAN3_HVBContactorSta: implementation-data-type=uint8
    DT_CAN3_SG_FD3_C100_0
      element CAN3_BatteryMode: implementation-data-type=uint8
      element CAN3_Rr_Coolantflow: implementation-data-type=uint8
      element CAN3_Rr_Coolanttemp: implementation-data-type=uint16
    DT_CAN3_SG_FD3_VCU1
      5 x element, all with category=TYPE_REFERENCE, implementation-data-type=uint8:
        CAN3_ActiveDischReq
        CAN3_CS_VCU1
        CAN3_PwrSta
        CAN3_RC_VCU1
        CAN3_ShiftGearPosn
    DT_CAN3_SG_FD3_VCU2
      11 x element, all with category=TYPE_REFERENCE:
        CAN3_CS_VCU2_CAN1: implementation-data-type=uint8
        CAN3_RC_VCU2_CAN1: implementation-data-type=uint8
        CAN3_Rr_ActvDmpDisabReq: implementation-data-type=uint8
        CAN3_Rr_IdcMax: implementation-data-type=uint16
        CAN3_Rr_IdcMin: implementation-data-type=uint16
        CAN3_Rr_MCUEnaReq: implementation-data-type=uint8
        CAN3_Rr_TMTqReq: implementation-data-type=uint16
        CAN3_Rr_TorqMax: implementation-data-type=uint16
        CAN3_Rr_TorqMin: implementation-data-type=uint16
        CAN3_Rr_UdcMax: implementation-data-type=uint16
        CAN3_Rr_UdcMin: implementation-data-type=uint16
    DT_CAN3_SG_FD3_VCU5
      7 x element, all with category=TYPE_REFERENCE:
        CAN3_FDC_VCU_RrSpdMax_Req: implementation-data-type=uint16
        CAN3_FDC_VCU_RrSpdMin_Req: implementation-data-type=uint16
        CAN3_FDC_VCU_RrTMCtrlMode_Req: implementation-data-type=uint8
        CAN3_FDC_VCU_RrTMSpd_Req: implementation-data-type=uint16
        CAN3_FDC_VCU_RrTMTq_Req: implementation-data-type=uint16
        CAN3_FDC_VCU_RrTqMax_Req: implementation-data-type=uint16
        CAN3_FDC_VCU_RrTqMin_Req: implementation-data-type=uint16
    DT_CAN3_SG_GW3_CE100_0
      6 x element, all with category=TYPE_REFERENCE:
        CAN3_IVI_Time_Day: implementation-data-type=uint8
        CAN3_IVI_Time_Hour: implementation-data-type=uint8
        CAN3_IVI_Time_Minute: implementation-data-type=uint8
        CAN3_IVI_Time_Month: implementation-data-type=uint8
        CAN3_IVI_Time_Second: implementation-data-type=uint8
        CAN3_VehSpeed: implementation-data-type=uint16
    DT_CAN3_SG_MCU_B_R1
      29 x element, all with category=TYPE_REFERENCE:
        CAN3_MCUWarn_R: implementation-data-type=uint8
        CAN3_MCU_B_R_IGBTDdeTemp_Sta: implementation-data-type=uint16
        CAN3_MCU_B_R_RealPwrKw_Sta: implementation-data-type=uint16
        CAN3_Rr_ActvDmpDisabSta: implementation-data-type=uint8
        CAN3_Rr_EDUDrtSta: implementation-data-type=uint8
        CAN3_Rr_EDUOpratingSta: implementation-data-type=uint8
        CAN3_Rr_EDURealTMTq: implementation-data-type=uint16
        CAN3_Rr_EDURotateDirction: implementation-data-type=uint8
        CAN3_Rr_EDUTqReqFbk: implementation-data-type=uint16
        CAN3_Rr_MCU1Chksum: implementation-data-type=uint8
        CAN3_Rr_MCU1RolCnt: implementation-data-type=uint8
        CAN3_Rr_MCUBAT: implementation-data-type=uint8
        CAN3_Rr_MCUDCBusCurr: implementation-data-type=uint16
        CAN3_Rr_MCUDCBusVolt: implementation-data-type=uint16
        CAN3_Rr_MCUDischrgSta: implementation-data-type=uint8
        CAN3_Rr_MCUEnaSta: implementation-data-type=uint8
        CAN3_Rr_MCUErr: implementation-data-type=uint8
        CAN3_Rr_MCUIGN_sta: implementation-data-type=uint8
        CAN3_Rr_MCUReady: implementation-data-type=uint8
        CAN3_Rr_MCUReady4Pre: implementation-data-type=uint8
        CAN3_Rr_MCUSysSta: implementation-data-type=uint8
        CAN3_Rr_MCUTemp: implementation-data-type=uint16
        CAN3_Rr_MotorAvailTq: implementation-data-type=uint16
        CAN3_Rr_RegenAvailTq: implementation-data-type=uint16
        CAN3_Rr_Reserved_bits: implementation-data-type=uint8
        CAN3_Rr_TMSpd: implementation-data-type=uint16
        CAN3_Rr_TMTemp: implementation-data-type=uint16
        CAN3_Rr_TMid: implementation-data-type=uint16
        CAN3_Rr_TMiq: implementation-data-type=uint16
    DT_CAN3_SG_MCU_B_R2
      16 x element, all with category=TYPE_REFERENCE:
        CAN3_MCU_B_R_FailLv_Sta: implementation-data-type=uint8
        CAN3_MCU_B_R_KL302TqCnt_Sta: implementation-data-type=uint8
        CAN3_MCU_B_R_LLCTempWarn_Sta: implementation-data-type=uint8
        CAN3_Rr_CoolanttempReq: implementation-data-type=uint16
        CAN3_Rr_Failcode1: implementation-data-type=uint8
        CAN3_Rr_Failcode2: implementation-data-type=uint8
        CAN3_Rr_Failcodehistory1: implementation-data-type=uint8
        CAN3_Rr_Failcodehistory2: implementation-data-type=uint8
        CAN3_Rr_LLCTemp: implementation-data-type=uint16
        CAN3_Rr_LLCflowReq: implementation-data-type=uint8
        CAN3_Rr_MCU2Chksum: implementation-data-type=uint8
        CAN3_Rr_MCU2RolCnt: implementation-data-type=uint8
        CAN3_Rr_MCU3_HW_Ver: implementation-data-type=uint16
        CAN3_Rr_MCU3_SW_Ver: implementation-data-type=uint16
        CAN3_Rr_MCUTempWarn: implementation-data-type=uint8
        CAN3_Rr_TMTempWarn: implementation-data-type=uint8
    DT_CAN3_SG_MCU_B_R_Debug1
      14 x element, all with category=TYPE_REFERENCE:
        CAN3_MCU_R_ID_REF: implementation-data-type=uint32
        CAN3_MCU_R_IQ_REF: implementation-data-type=uint32
        CAN3_MCU_R_Reserve{0..2}: implementation-data-type=uint16
        CAN3_R_FD_FACTCODE_N: implementation-data-type=uint8
        CAN3_R_FD_FACTCODE_P: implementation-data-type=uint8
        CAN3_R_ID_TQ_LIM_N: implementation-data-type=uint8
        CAN3_R_ID_TQ_LIM_P: implementation-data-type=uint8
        CAN3_R_K_TQ_LIM_N: implementation-data-type=uint8
        CAN3_R_K_TQ_LIM_P: implementation-data-type=uint8
        CAN3_R_OffsetAngle: implementation-data-type=uint16
        CAN3_R_TQ_LIM_N: implementation-data-type=uint8
        CAN3_R_TQ_LIM_P: implementation-data-type=uint8
    DT_CAN3_SG_MCU_FVT_R1
      9 x element, all with category=TYPE_REFERENCE:
        CAN3_MCU_FVT_R_BoostOP_Sta: implementation-data-type=uint8
        CAN3_MCU_FVT_R_EDUTqReq_Fbk: implementation-data-type=uint16
        CAN3_MCU_FVT_R_Failcode3_Sta: implementation-data-type=uint8
        CAN3_MCU_FVT_R_HeatingOP_Sta: implementation-data-type=uint8
        CAN3_MCU_FVT_R_MCUBAT_Sta: implementation-data-type=uint16
        CAN3_MCU_FVT_R_MCUErr_Sta: implementation-data-type=uint8
        CAN3_MCU_FVT_R_MCUSys_Sta: implementation-data-type=uint8
        CAN3_MCU_FVT_R_OilTemp_Sta: implementation-data-type=uint16
        CAN3_MCU_FVT_R_TMSpd_Sta: implementation-data-type=uint16
